# ATtiny26 register map
Vendor: Atmel; File version: 1.0
CPU: other r0p0, little endian, no MPU, no FPU, 4 interrupt priority bits
Registers are 8-bit, read-write, reset 0x0 unless marked. A register's access mark holds for its fields unless they carry their own. Offsets are from the block's base; lines under a group give offsets from that group; [hi:lo] are bit positions; {n}, {i} and the like mark numbered series; 'fields as' and 'values as' point back to an identical list; <NAME> marks a mode.

## Memory map
0x00800024 ADC size 0x4 — Analog-to-Digital Converter
0x00800028 AC size 0x1 — Analog Comparator
0x0080002D USI size 0x3 — Universal Serial Interface
0x00800036 PORTB size 0x3 — I/O Port
0x00800039 PORTA size 0x3 — I/O Port
0x0080003C EEPROM size 0x3
0x00800041 WDT size 0x1 — Watchdog Timer
0x00800049 TC1 blocks up to offset 0x11 — Timer/Counter, 8-bit
0x00800051 CPU blocks up to offset 0xF — CPU Registers
0x00800052 TC0 blocks up to offset 0x8 — Timer/Counter, 8-bit
0x0080005A EXINT size 0x2 — External Interrupts

## Interrupts
0 RESET (CPU) — External Reset, Power-on Reset and Watchdog Reset
1 INT0 (CPU) — External Interrupt 0
2 IO_PINS (CPU) — External Interrupt Request 0
3 TIMER1_CMPA (CPU) — Timer/Counter1 Compare Match 1A
4 TIMER1_CMPB (CPU) — Timer/Counter1 Compare Match 1B
5 TIMER1_OVF1 (CPU) — Timer/Counter1 Overflow
6 TIMER0_OVF0 (CPU) — Timer/Counter0 Overflow
7 USI_STRT (CPU) — USI Start
8 USI_OVF (CPU) — USI Overflow
9 EE_RDY (CPU) — EEPROM Ready
10 ANA_COMP (CPU) — Analog Comparator
11 ADC (CPU) — ADC Conversion Complete

## AC — Analog Comparator
Base 0x00800028
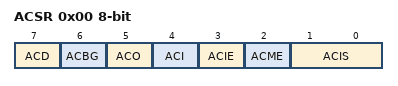
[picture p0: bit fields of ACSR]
0x00 ACSR — Analog Comparator Control And Status Register
  [7] ACD — Analog Comparator Disable
  [6] ACBG — Analog Comparator Bandgap Select
  [5] ACO — Analog Compare Output
  [4] ACI — Analog Comparator Interrupt Flag
  [3] ACIE — Analog Comparator Interrupt Enable
  [2] ACME — Analog Comparator Multiplexer Enable
  [1:0] ACIS — Analog Comparator Interrupt Mode Select bits
    0=INTERRUPT_ON_TOGGLE; 2=INTERRUPT_ON_FALLING_EDGE; 3=INTERRUPT_ON_RISING_EDGE

## ADC — Analog-to-Digital Converter
Base 0x00800024
0x00 ADC 16-bit (reset mask 0xFF) — ADC Data Register Bytes
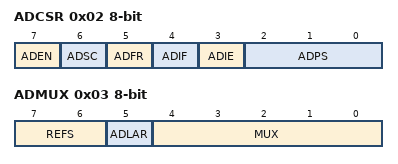
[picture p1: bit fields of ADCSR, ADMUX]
0x02 ADCSR — The ADC Control and Status register
  [7] ADEN — ADC Enable
  [6] ADSC — ADC Start Conversion
  [5] ADFR — ADC Free Running Select
  [4] ADIF — ADC Interrupt Flag
  [3] ADIE — ADC Interrupt Enable
  [2:0] ADPS — ADC Prescaler Select Bits
    1=2; 2=4; 3=8; 4=16; 5=32; 6=64; 7=128
0x03 ADMUX — The ADC multiplexer Selection Register
  [7:6] REFS — Reference Selection Bits
    0=AVCC; 1=AREF; 2=INTERNAL_VOLTAGE_REFERANCE (Internal Voltage Reference); 3=INTERNAL_VOLTAGE_REFERENCE_WITH_EXTERNAL_CAPACITOR_AT_AREF_PIN
  [5] ADLAR — Left Adjust Result
  [4:0] MUX — Analog Channel and Gain Selection Bits

## CPU — CPU Registers
Base 0x00800051
0x00 OSCCAL — Status Register
  [7:0] OSCCAL — Oscillator Calibration
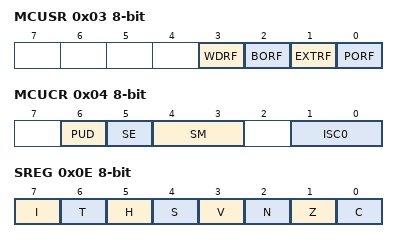
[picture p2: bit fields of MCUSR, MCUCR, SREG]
0x03 MCUSR — MCU Status register
  [3] WDRF — Watchdog Reset Flag
  [2] BORF — Brown-out Reset Flag
  [1] EXTRF — External Reset Flag
  [0] PORF — Power-On Reset Flag
0x04 MCUCR — MCU Control Register
  [6] PUD — Pull-up Disable
  [5] SE — Sleep Enable
  [4:3] SM — Sleep Mode Select Bits
    0=IDLE; 1=ADC (ADC Noise Reduction (If Available)); 2=PDOWN (Power Down); 3=STDBY (Standby)
  [1:0] ISC0 — Interrupt Sense Control 0 bits
    0=LOW_LEVEL_OF_INTX; 1=ANY_LOGICAL_CHANGE_IN_INTX; 2=FALLING_EDGE_OF_INTX; 3=RISING_EDGE_OF_INTX
0x0C SP — Stack Pointer
0x0E SREG — Status Register
  [7] I — Global Interrupt Enable
  [6] T — Bit Copy Storage
  [5] H — Half Carry Flag
  [4] S — Sign Bit
  [3] V — Two's Complement Overflow Flag
  [2] N — Negative Flag
  [1] Z — Zero Flag
  [0] C — Carry Flag

## EEPROM
Base 0x0080003C
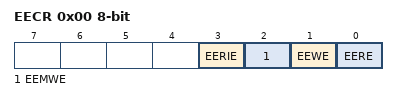
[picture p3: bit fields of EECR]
0x00 EECR — EEPROM Control Register
  [3] EERIE — EEProm Ready Interrupt Enable
  [2] EEMWE — EEPROM Master Write Enable
  [1] EEWE — EEPROM Write Enable
  [0] EERE — EEPROM Read Enable
0x01 EEDR — EEPROM Data Register
0x02 EEAR — EEPROM Read/Write Access
